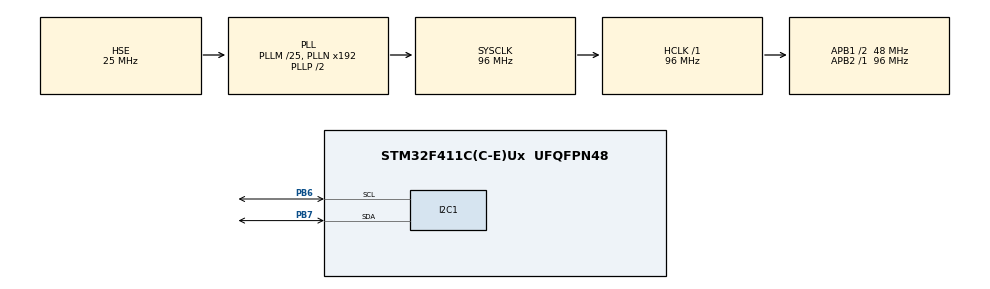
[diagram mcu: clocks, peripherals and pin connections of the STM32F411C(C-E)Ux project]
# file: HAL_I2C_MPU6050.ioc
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Mcu.Family=STM32F4
Mcu.Name=STM32F411C(C-E)Ux
Mcu.Package=UFQFPN48
NVIC.PriorityGroup=NVIC_PRIORITYGROUP_4
PA13.Mode=Trace_Asynchronous_SW
PA13.Signal=SYS_JTMS-SWDIO
PA14.Mode=Trace_Asynchronous_SW
PA14.Signal=SYS_JTCK-SWCLK
PB3.Mode=Trace_Asynchronous_SW
PB3.Signal=SYS_JTDO-SWO
PB6.Mode=I2C
PB6.Signal=I2C1_SCL
PB7.Mode=I2C
PB7.Signal=I2C1_SDA
PH0\ -\ OSC_IN.Mode=HSE-External-Oscillator
PH0\ -\ OSC_IN.Signal=RCC_OSC_IN
PH1\ -\ OSC_OUT.Mode=HSE-External-Oscillator
PH1\ -\ OSC_OUT.Signal=RCC_OSC_OUT
ProjectManager.HeapSize=0x200
ProjectManager.StackSize=0x400
ProjectManager.TargetToolchain=STM32CubeIDE
RCC.48MHZClocksFreq_Value=48000000
RCC.AHBFreq_Value=96000000
RCC.APB1CLKDivider=RCC_HCLK_DIV2
RCC.APB1Freq_Value=48000000
RCC.APB1TimFreq_Value=96000000
RCC.APB2Freq_Value=96000000
RCC.APB2TimFreq_Value=96000000
RCC.CortexFreq_Value=96000000
RCC.HCLKFreq_Value=96000000
RCC.HSE_VALUE=25000000
RCC.HSI_VALUE=16000000
RCC.LSE_VALUE=32768
RCC.PLLM=25
RCC.PLLSourceVirtual=RCC_PLLSOURCE_HSE
RCC.SYSCLKFreq_VALUE=96000000
RCC.SYSCLKSource=RCC_SYSCLKSOURCE_PLLCLK
RCC.VCOOutputFreq_Value=192000000
board=custom

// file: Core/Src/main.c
/* USER CODE BEGIN Header */
/**
  ******************************************************************************
  * @file           : main.c
  * @brief          : Main program body
  ******************************************************************************
  * @attention
  *
  * Copyright (c) 2022 STMicroelectronics.
  * All rights reserved.
  *
  * This software is licensed under terms that can be found in the LICENSE file
  * in the root directory of this software component.
  * If no LICENSE file comes with this software, it is provided AS-IS.
  *
  ******************************************************************************
  */
/* USER CODE END Header */
#include "main.h"

/* USER CODE BEGIN Includes */

#include <i2c.h>
#include <mpu6050.h>
#include <stdio.h>

/* USER CODE END Includes */

// I2C_HandleTypeDef hi2c1;

/* USER CODE BEGIN PV */

MPU6050_ACCEL_t Mpu_Accel;
MPU6050_GYRO_t Mpu_Gyro;

/* USER CODE END PV */

void SystemClock_Config(void);
static void MX_GPIO_Init(void);
//static void MX_I2C1_Init(void);
/* USER CODE BEGIN PFP */

int _write(int file, char *ptr, int len);

/* USER CODE END PFP */

int main(void)
{

  /* MCU Configuration--------------------------------------------------------*/

  /* Reset of all peripherals, Initializes the Flash interface and the Systick. */
  HAL_Init();

  /* Configure the system clock */
  SystemClock_Config();

  /* Initialize all configured peripherals */
  MX_GPIO_Init();
  MX_I2C1_Init();
  /* USER CODE BEGIN 2 */

  MPU6050_Init();
  printf(" \n Initialized \n");

  /* USER CODE END 2 */

  /* Infinite loop */
  while (1)
  {

  	  MPU6050_Read_Accel(&Mpu_Accel);
  	  MPU6050_Read_Gyro(&Mpu_Gyro);

  	  printf("\n Accelerometer Readings \n");
  	  printf(" Ax = %.2f g \n", Mpu_Accel.Accel_X);
  	  printf(" Ay = %.2f g \n", Mpu_Accel.Accel_Y);
  	  printf(" Az = %.2f g \n", Mpu_Accel.Accel_Z);

  	  printf("\n Gyroscope Readings \n");
  	  printf(" Gx = %.2f \n", Mpu_Gyro.Gyro_X);
  	  printf(" Gy = %.2f \n", Mpu_Gyro.Gyro_Y);
  	  printf(" Gz = %.2f \n", Mpu_Gyro.Gyro_Z);

  }
}

void SystemClock_Config(void)
{
  RCC_OscInitTypeDef RCC_OscInitStruct = {0};
  RCC_ClkInitTypeDef RCC_ClkInitStruct = {0};

  /** Configure the main internal regulator output voltage
  */
  __HAL_RCC_PWR_CLK_ENABLE();
  __HAL_PWR_VOLTAGESCALING_CONFIG(PWR_REGULATOR_VOLTAGE_SCALE1);

  /** Initializes the RCC Oscillators according to the specified parameters
  * in the RCC_OscInitTypeDef structure.
  */
  RCC_OscInitStruct.OscillatorType = RCC_OSCILLATORTYPE_HSE;
  RCC_OscInitStruct.HSEState = RCC_HSE_ON;
  RCC_OscInitStruct.PLL.PLLState = RCC_PLL_ON;
  RCC_OscInitStruct.PLL.PLLSource = RCC_PLLSOURCE_HSE;
  RCC_OscInitStruct.PLL.PLLM = 25;
  RCC_OscInitStruct.PLL.PLLN = 192;
  RCC_OscInitStruct.PLL.PLLP = RCC_PLLP_DIV2;
  RCC_OscInitStruct.PLL.PLLQ = 4;
  if (HAL_RCC_OscConfig(&RCC_OscInitStruct) != HAL_OK)
  {
    Error_Handler();
  }

  /** Initializes the CPU, AHB and APB buses clocks
  */
  RCC_ClkInitStruct.ClockType = RCC_CLOCKTYPE_HCLK|RCC_CLOCKTYPE_SYSCLK
                              |RCC_CLOCKTYPE_PCLK1|RCC_CLOCKTYPE_PCLK2;
  RCC_ClkInitStruct.SYSCLKSource = RCC_SYSCLKSOURCE_PLLCLK;
  RCC_ClkInitStruct.AHBCLKDivider = RCC_SYSCLK_DIV1;
  RCC_ClkInitStruct.APB1CLKDivider = RCC_HCLK_DIV2;
  RCC_ClkInitStruct.APB2CLKDivider = RCC_HCLK_DIV1;

  if (HAL_RCC_ClockConfig(&RCC_ClkInitStruct, FLASH_LATENCY_3) != HAL_OK)
  {
    Error_Handler();
  }
}

//static void MX_I2C1_Init(void)
//{
//
//  /* USER CODE BEGIN I2C1_Init 0 */
//
//  /* USER CODE END I2C1_Init 0 */
//
//  /* USER CODE BEGIN I2C1_Init 1 */
//
//  /* USER CODE END I2C1_Init 1 */
//  hi2c1.Instance = I2C1;
//  hi2c1.Init.ClockSpeed = 100000;
//  hi2c1.Init.DutyCycle = I2C_DUTYCYCLE_2;
//  hi2c1.Init.OwnAddress1 = 0;
//  hi2c1.Init.AddressingMode = I2C_ADDRESSINGMODE_7BIT;
//  hi2c1.Init.DualAddressMode = I2C_DUALADDRESS_DISABLE;
//  hi2c1.Init.OwnAddress2 = 0;
//  hi2c1.Init.GeneralCallMode = I2C_GENERALCALL_DISABLE;
//  hi2c1.Init.NoStretchMode = I2C_NOSTRETCH_DISABLE;
//  if (HAL_I2C_Init(&hi2c1) != HAL_OK)
//  {
//    Error_Handler();
//  }
//  /* USER CODE BEGIN I2C1_Init 2 */
//
//  /* USER CODE END I2C1_Init 2 */
//
//}

static void MX_GPIO_Init(void)
{

  /* GPIO Ports Clock Enable */
  __HAL_RCC_GPIOH_CLK_ENABLE();
  __HAL_RCC_GPIOA_CLK_ENABLE();
  __HAL_RCC_GPIOB_CLK_ENABLE();

}

/* USER CODE BEGIN 4 */

int _write(int file, char *ptr, int len)
{
  /* Implement your write code here, this is used by puts and printf for example */
  int i=0;
  for(i=0 ; i<len ; i++)
    ITM_SendChar((*ptr++));
  return len;
}

/* USER CODE END 4 */

void Error_Handler(void)
{
  __disable_irq();
  while (1)
  {
  }
}
